# RockChip_RK3588 register map
Vendor: RockChip Electronics Co., Ltd.; Series: RK3588; File version: 0.1
Registers are 32-bit, read-write, no defined reset value unless marked. A register's access mark holds for its fields unless they carry their own. Offsets are from the block's base; [hi:lo] are bit positions; {n}, {i} and the like mark numbered series.

## KEYLADDER_S
Base 0xFE380000
0x00 CLK_CTL — Clock Control Register
0x04 RST_CTL — Reset Control Register
0x08 DMA_INT_EN — DMA Interrupt Enable Register
0x0C DMA_INT_ST — DMA Interrupt Status Register
0x10 DMA_CTL — DMA Control Register
0x14 DMA_LLI_ADDR — DMA LIST Start Address Register
0x18 DMA_ST — DMA Status Register
0x1C DMA_STATE
0x20 DMA_LLI_RADDR — DMA LLI Read Address Register
0x24 DMA_SRC_RADDR — DMA Source Data Read Address Register
0x28 DMA_DST_WADDR — DMA Destination Data Read Address Register
0x2C DMA_ITEM_ID — DMA Descriptor ID Register
0x40 FIFO_CTL — FIFO Control Register
0x44 BC_CTL — Block Cipher Control Register
0x4C CIPHER_ST — Cipher Status Register
0x50 CIPHER_STATE — Cipher Current State Register
{0x100+4i} CH0_IV_{i} (i=0..3) — iv {i}
{0x180+4i} CH0_KEY_{i} (i=0..3) — key {i}
0x450 APB_CMD — apb master command enable
0x454 APB_PADDR
0x458 APB_PWDATA
0x45C APB_PWRITE
0x608 INTER_COPY — key table internal copy
0x60C OTP_COPY — OTP key COPY
0x610 KEY_SEL — Operation key select
0x618 LOCKSTEP_FLAG — Lockstep mistake flag
0x61C LOCKSTEP_EN — Lockstep check enable
0x620 SRC_NUM_SEL — Source key select
0x624 SRC_NUM_DONE — Source key cache flag
0x680 AES_VERSION — AES version code is 0x0007_0033
0x684 DES_VERSION — DES version code is 0x0003_0033
0x688 SM4_VERSION — SM4 version code is 0x0000_0033
0x68C HASH_VERSION — HASH version code is 0x0000_0000
0x690 HMAC_VERSION — HMAC version code is 0x0000_0000
0x694 RNG_VERSION — RNG version code is 0x0200_0000
0x698 PKA_VERSION — PKA version code is 0x0000_0000
0x6F0 CRYPTO_VERSION — KEYLAD version code is 0x0200_0003

## SGRF_BUS
Base 0xFD586000
{0x0+4i} SOC_CON{i} (i=0..19)
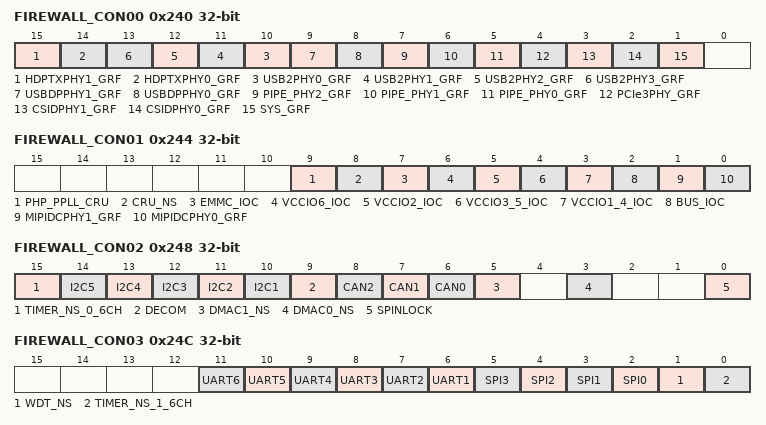
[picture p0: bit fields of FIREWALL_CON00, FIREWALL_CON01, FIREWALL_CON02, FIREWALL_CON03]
0x240 FIREWALL_CON00
  [all] fields
    0=NON_SECURE; 1=SECURE
  [15] HDPTXPHY1_GRF
  [14] HDPTXPHY0_GRF
  [n+10] USB2PHY{n}_GRF (n=0..3)
  [9] USBDPPHY1_GRF
  [8] USBDPPHY0_GRF
  [7] PIPE_PHY2_GRF
  [6] PIPE_PHY1_GRF
  [5] PIPE_PHY0_GRF
  [4] PCIe3PHY_GRF
  [3] CSIDPHY1_GRF
  [2] CSIDPHY0_GRF
  [1] SYS_GRF
0x244 FIREWALL_CON01
  [all] fields
    0=NON_SECURE; 1=SECURE
  [9] PHP_PPLL_CRU
  [8] CRU_NS
  [7] EMMC_IOC
  [6] VCCIO6_IOC
  [5] VCCIO2_IOC
  [4] VCCIO3_5_IOC
  [3] VCCIO1_4_IOC
  [2] BUS_IOC
  [1] MIPIDCPHY1_GRF
  [0] MIPIDCPHY0_GRF
0x248 FIREWALL_CON02
  [all] fields
    0=NON_SECURE; 1=SECURE
  [15] TIMER_NS_0_6CH
  [n+9] I2C{n} (n=1..5)
  [9] DECOM
  [8] CAN2
  [7] CAN1
  [6] CAN0
  [5] DMAC1_NS
  [3] DMAC0_NS
  [0] SPINLOCK
0x24C FIREWALL_CON03
  [all] fields
    0=NON_SECURE; 1=SECURE
  [n+5] UART{n} (n=1..6)
  [n+2] SPI{n} (n=0..3)
  [1] WDT_NS
  [0] TIMER_NS_1_6CH
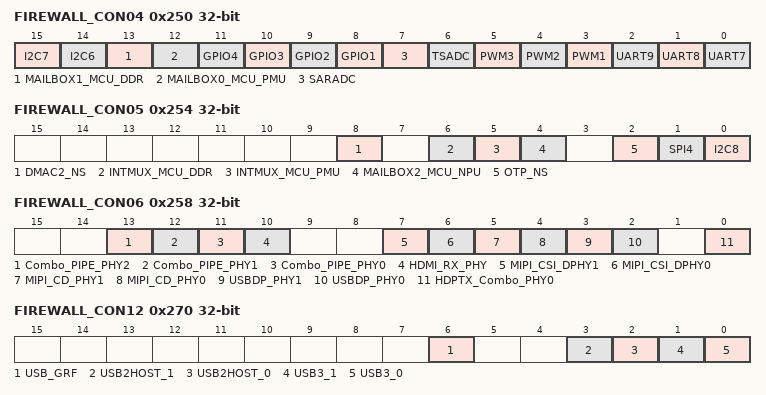
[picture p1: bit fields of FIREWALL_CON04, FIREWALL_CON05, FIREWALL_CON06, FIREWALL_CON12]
0x250 FIREWALL_CON04
  [all] fields
    0=NON_SECURE; 1=SECURE
  [15] I2C7
  [14] I2C6
  [13] MAILBOX1_MCU_DDR
  [12] MAILBOX0_MCU_PMU
  [n+7] GPIO{n} (n=1..4)
  [7] SARADC
  [6] TSADC
  [5] PWM3
  [4] PWM2
  [3] PWM1
  [2] UART9
  [1] UART8
  [0] UART7
0x254 FIREWALL_CON05
  [all] fields
    0=NON_SECURE; 1=SECURE
  [8] DMAC2_NS
  [6] INTMUX_MCU_DDR
  [5] INTMUX_MCU_PMU
  [4] MAILBOX2_MCU_NPU
  [2] OTP_NS
  [1] SPI4
  [0] I2C8
0x258 FIREWALL_CON06
  [all] fields
    0=NON_SECURE; 1=SECURE
  [13] Combo_PIPE_PHY2
  [12] Combo_PIPE_PHY1
  [11] Combo_PIPE_PHY0
  [10] HDMI_RX_PHY
  [7] MIPI_CSI_DPHY1
  [6] MIPI_CSI_DPHY0
  [5] MIPI_CD_PHY1
  [4] MIPI_CD_PHY0
  [3] USBDP_PHY1
  [2] USBDP_PHY0
  [0] HDPTX_Combo_PHY0
0x25C FIREWALL_CON07
  [2] PCIe3_PHY
    0=NON_SECURE; 1=SECURE
{0x240+4i} FIREWALL_CON{i:02} (i=8..11)
0x270 FIREWALL_CON12
  [all] fields
    0=NON_SECURE; 1=SECURE
  [6] USB_GRF
  [3] USB2HOST_1
  [2] USB2HOST_0
  [1] USB3_1
  [0] USB3_0
0x274 FIREWALL_CON13
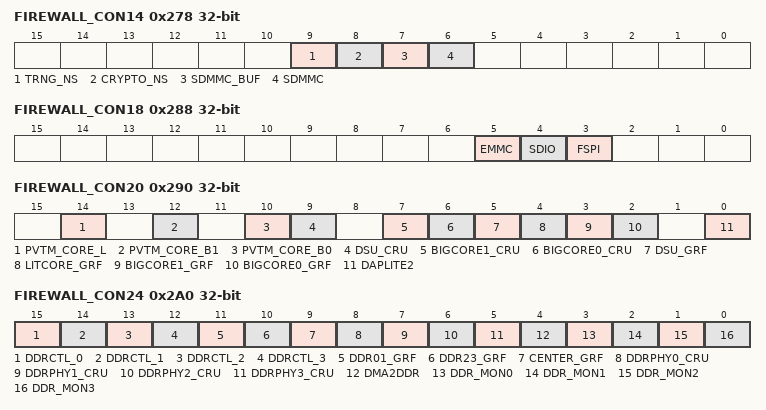
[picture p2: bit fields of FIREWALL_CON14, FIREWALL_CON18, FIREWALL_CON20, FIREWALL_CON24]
0x278 FIREWALL_CON14
  [all] fields
    0=NON_SECURE; 1=SECURE
  [9] TRNG_NS
  [8] CRYPTO_NS
  [7] SDMMC_BUF
  [6] SDMMC
{0x240+4i} FIREWALL_CON{i} (i=15..17)
0x288 FIREWALL_CON18
  [all] fields
    0=NON_SECURE; 1=SECURE
  [5] EMMC
  [4] SDIO
  [3] FSPI
0x28C FIREWALL_CON19
0x290 FIREWALL_CON20
  [all] fields
    0=NON_SECURE; 1=SECURE
  [14] PVTM_CORE_L
  [12] PVTM_CORE_B1
  [10] PVTM_CORE_B0
  [9] DSU_CRU
  [7] BIGCORE1_CRU
  [6] BIGCORE0_CRU
  [5] DSU_GRF
  [4] LITCORE_GRF
  [3] BIGCORE1_GRF
  [2] BIGCORE0_GRF
  [0] DAPLITE2
{0x240+4i} FIREWALL_CON{i} (i=21..23)
0x2A0 FIREWALL_CON24
  [all] fields
    0=NON_SECURE; 1=SECURE
  [15-n] DDRCTL_{n} (n=0..3)
  [11] DDR01_GRF
  [10] DDR23_GRF
  [9] CENTER_GRF
  [8-n] DDRPHY{n}_CRU (n=0..3)
  [4] DMA2DDR
  [3-n] DDR_MON{n} (n=0..3)
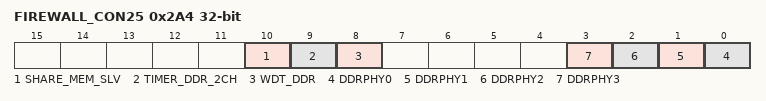
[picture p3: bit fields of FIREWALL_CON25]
0x2A4 FIREWALL_CON25
  [all] fields
    0=NON_SECURE; 1=SECURE
  [10] SHARE_MEM_SLV
  [9] TIMER_DDR_2CH
  [8] WDT_DDR
  [n] DDRPHY{n} (n=0..3)
{0x240+4i} FIREWALL_CON{i} (i=26..31)

## SGRF_DSU
Base 0xFD587000
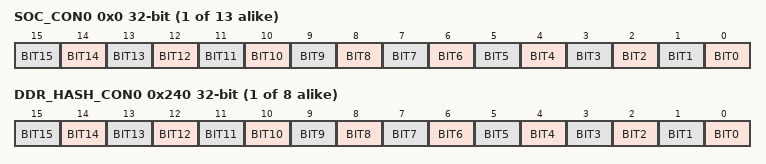
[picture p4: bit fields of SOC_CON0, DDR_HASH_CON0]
{0x0+4i} SOC_CON{i} (i=0..12)
  [n] BIT{n} (n=0..15)
{0x240+4i} DDR_HASH_CON{i} (i=0..7)
  [n] BIT{n} (n=0..15)

## SGRF_PMU1
Base 0xFD582000
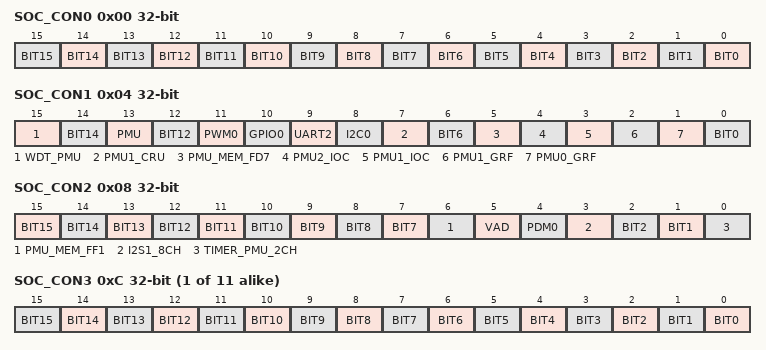
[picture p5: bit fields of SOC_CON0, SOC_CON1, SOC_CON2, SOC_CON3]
0x00 SOC_CON0
  [n] BIT{n} (n=0..15)
0x04 SOC_CON1
  [15] WDT_PMU, [14] BIT14, [13] PMU, [12] BIT12, [11] PWM0, [10] GPIO0, [9] UART2, [8] I2C0, [7] PMU1_CRU, [6] BIT6, [5] PMU_MEM_FD7, [4] PMU2_IOC, [3] PMU1_IOC, [2] PMU1_GRF, [1] PMU0_GRF, [0] BIT0
0x08 SOC_CON2
  [n] BIT{n} (n=7..15), [6] PMU_MEM_FF1, [5] VAD, [4] PDM0, [3] I2S1_8CH, [2] BIT2, [1] BIT1, [0] TIMER_PMU_2CH
{0x0+4i} SOC_CON{i} (i=3..13)
  [n] BIT{n} (n=0..15)
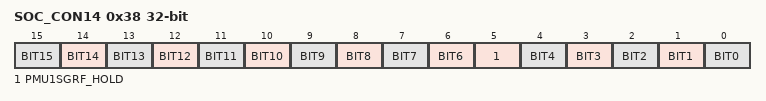
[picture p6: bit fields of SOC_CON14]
0x38 SOC_CON14
  [n] BIT{n} (n=6..15), [5] PMU1SGRF_HOLD, [n] BIT{n} (n=0..4)
